# HK32L0xx register map
Vendor: HKMicroChip Ltd.; Series: HK32L0xx; File version: 1.3
CPU: CM0 r0p0, little endian, no MPU, no FPU, 3 interrupt priority bits
Registers are 32-bit, read-write, reset 0x0 unless marked. A register's access mark holds for its fields unless they carry their own. Offsets are from the block's base; [hi:lo] are bit positions.

## IWDG
Base 0x40003000
0x00 KR wo
  [15:0] KEY — Key value
0x04 PR
  [2:0] PR — Prescaler divider
0x08 RLR reset 0xFFF
  [11:0] RL — Watchdog counter reload value
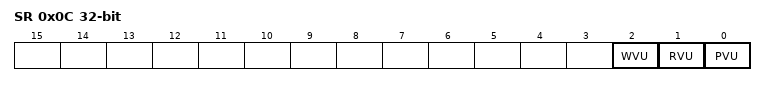
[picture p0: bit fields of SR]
0x0C SR ro
  [2] WVU — Watchdog counter window value update
  [1] RVU — Watchdog counter reload value update
  [0] PVU — Watchdog prescaler value update
0x10 WINR reset 0xFFF
  [11:0] WIN — Watchdog counter window value

## WWDG
Base 0x40002C00
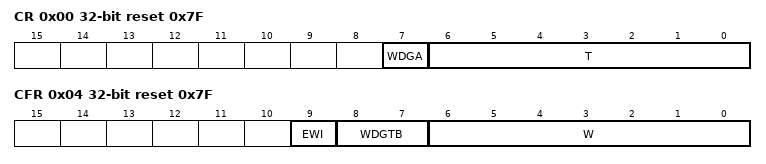
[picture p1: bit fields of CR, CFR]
0x00 CR reset 0x7F
  [7] WDGA — Activation bit
  [6:0] T — 7-bit counter (MSB to LSB)
0x04 CFR reset 0x7F
  [9] EWI — Early wakeup interrupt
  [8:7] WDGTB — Timer base
  [6:0] W — 7-bit window value
0x08 SR
  [0] EWIF — Early wakeup interrupt flag

## I2C1
Base 0x40005400
Same registers: I2C2 0x40005800
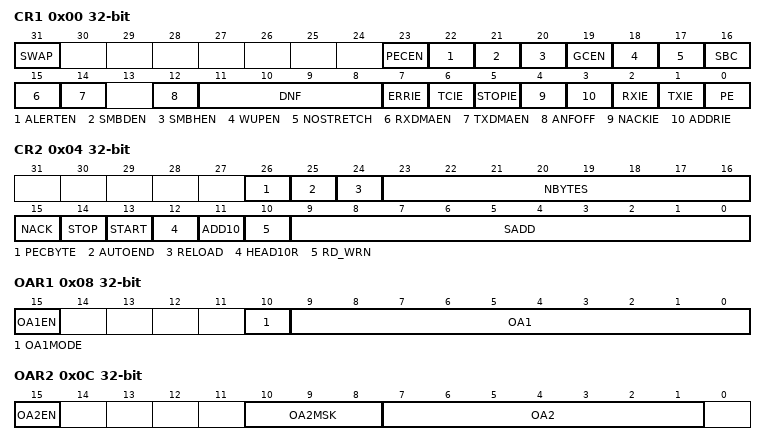
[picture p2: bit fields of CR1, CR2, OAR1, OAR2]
0x00 CR1
  [31] SWAP — Exchange SDA/SCL pin
  [23] PECEN — PEC enable
  [22] ALERTEN — SMBus alert enable
  [21] SMBDEN — SMBus Device Default address enable
  [20] SMBHEN — SMBus Host address enable
  [19] GCEN — General call enable
  [18] WUPEN — Wakeup from Stop mode enable
  [17] NOSTRETCH — Clock stretching disable
  [16] SBC — Slave byte control
  [15] RXDMAEN — DMA reception requests enable
  [14] TXDMAEN — DMA transmission requests enable
  [12] ANFOFF — Analog noise filter OFF
  [11:8] DNF — Digital noise filter
  [7] ERRIE — Error interrupts enable
  [6] TCIE — Transfer Complete interrupt enable
  [5] STOPIE — STOP detection Interrupt enable
  [4] NACKIE — Not acknowledge received Interrupt enable
  [3] ADDRIE — Address match Interrupt enable (slave only)
  [2] RXIE — RX Interrupt enable
  [1] TXIE — TX Interrupt enable
  [0] PE — Peripheral enable
0x04 CR2 access not given
  [26] PECBYTE rw — Packet error checking byte
  [25] AUTOEND rw — Automatic end mode (master mode)
  [24] RELOAD rw — NBYTES reload mode
  [23:16] NBYTES rw — Number of bytes
  [15] NACK rw — NACK generation (slave mode)
  [14] STOP rw — STOP generation (master mode)
  [13] START rw — Start generation
  [12] HEAD10R rw — 10-bit address header only read direction (master receiver mode)
  [11] ADD10 rw — 10-bit addressing mode (master mode)
  [10] RD_WRN rw — Transfer direction (master mode)
  [9:0] SADD
0x08 OAR1
  [15] OA1EN — Own Address 1 enable
  [10] OA1MODE — Own Address 1 10-bit mode
  [9:0] OA1
0x0C OAR2
  [15] OA2EN — Own Address 2 enable
  [10:8] OA2MSK — Own Address 2 masks
  [7:1] OA2 — Interface address
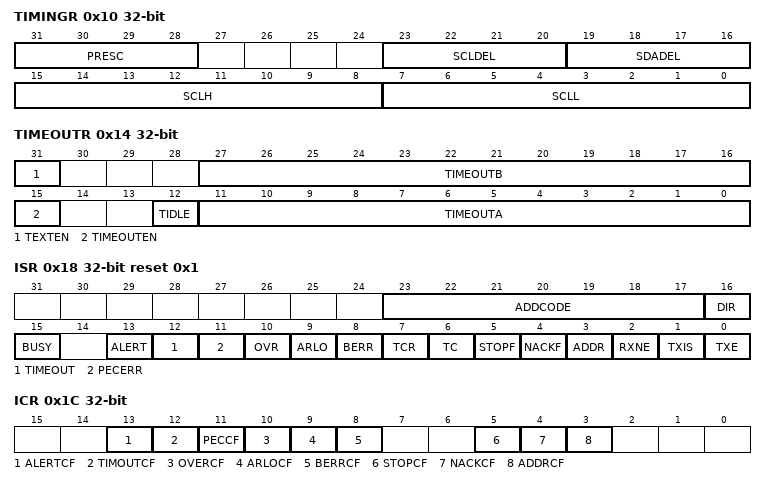
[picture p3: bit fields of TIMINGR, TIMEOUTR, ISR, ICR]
0x10 TIMINGR
  [31:28] PRESC — Timing prescaler
  [23:20] SCLDEL — Data setup time
  [19:16] SDADEL — Data hold time
  [15:8] SCLH — SCL high period (master mode)
  [7:0] SCLL — SCL low period (master mode)
0x14 TIMEOUTR
  [31] TEXTEN — Extended clock timeout enable
  [27:16] TIMEOUTB — Bus timeout B
  [15] TIMEOUTEN — Clock timeout enable
  [12] TIDLE — Idle clock timeout detection
  [11:0] TIMEOUTA — Bus Timeout A
0x18 ISR access per field reset 0x1
  [23:17] ADDCODE ro — Address match code (Slave mode)
  [16] DIR ro — Transfer direction (Slave mode)
  [15] BUSY ro — Bus busy
  [13] ALERT ro — SMBus alert
  [12] TIMEOUT ro — Timeout or tLOW detection flag
  [11] PECERR ro — PEC Error in reception
  [10] OVR ro — Overrun/Underrun (slave mode)
  [9] ARLO ro — Arbitration lost
  [8] BERR ro — Bus error
  [7] TCR ro — Transfer Complete Reload
  [6] TC ro — Transfer Complete (master mode)
  [5] STOPF ro — STOP detection flag
  [4] NACKF ro — Not Acknowledge received flag
  [3] ADDR ro — Address matched (slave mode)
  [2] RXNE ro — Receive data register not empty (receivers)
  [1] TXIS rw — Transmit interrupt status (transmitters)
  [0] TXE rw — Transmit data register empty (transmitters)
0x1C ICR wo
  [13] ALERTCF — Alert flag clear
  [12] TIMOUTCF — Timeout detection flag clear
  [11] PECCF — PEC Error flag clear
  [10] OVERCF — Overrun/Underrun flag clear
  [9] ARLOCF — Arbitration Lost flag clear
  [8] BERRCF — Bus error flag clear
  [5] STOPCF — STOP detection flag clear
  [4] NACKCF — Not Acknowledge flag clear
  [3] ADDRCF — Address matched flag clear
0x20 PECR ro
  [7:0] PEC — Packet error checking register
0x24 RXDR ro
  [7:0] RXDATA — 8-bit receive data
0x28 TXDR
  [7:0] TXDATA — 8-bit transmit data
